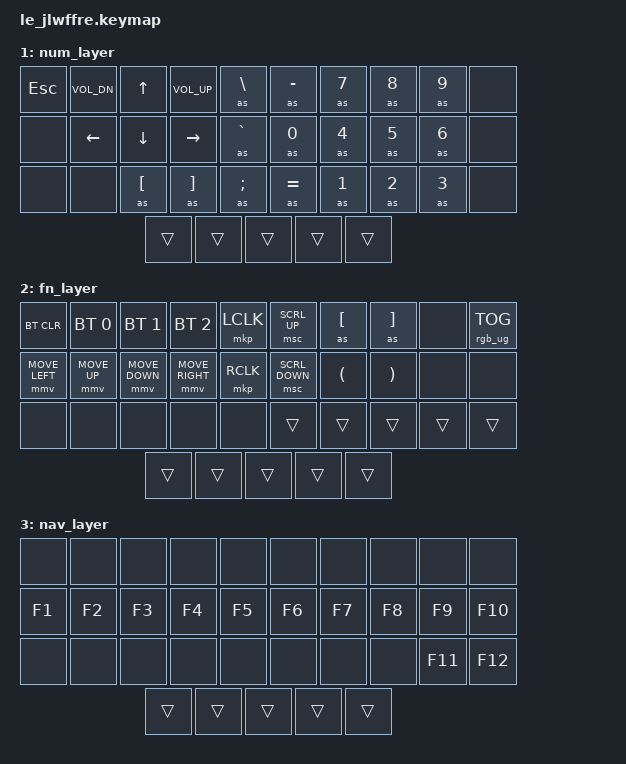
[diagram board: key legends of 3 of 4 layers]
/*
 * Copyright (c) 2022 The ZMK Contributors
 *
 * SPDX-License-Identifier: MIT
 */

#include <behaviors.dtsi>
#include <dt-bindings/zmk/keys.h>
#include <dt-bindings/zmk/bt.h>
#include <dt-bindings/zmk/pointing.h>
#include <dt-bindings/zmk/rgb.h>

// Home row mods macro - updated order: LSHIFT, LCTRL, lt 2, LALT (from center out)
#define HRML(k1,k2,k3,k4) &ht LALT k1 &lt 2 k2 &ht LCTRL k3 &ht LSHIFT k4
#define HRMR(k1,k2,k3,k4) &ht RSHIFT k1 &ht RCTRL k2 &lt 2 k3 &ht RALT k4

/ {

    behaviors {
        ht: hold_tap {
            compatible = "zmk,behavior-hold-tap";
            #binding-cells = <2>;   
            flavor = "balanced";
            tapping-term-ms = <200>;
            quick-tap-ms = <220>;
            require-prior-idle-ms = <125>;
            bindings = <&kp>, <&kp>;
        };
        mt: mod_tap {
            #binding-cells = <2>;
            tapping-term-ms = <200>;
            quick-tap-ms = <220>;
            require-prior-idle-ms = <125>;
            bindings = <&kp>, <&kp>;
        };
        as_ht: autoshift_hold_tap {
            compatible = "zmk,behavior-hold-tap";
            #binding-cells = <2>;
            tapping-term-ms = <200>;
            bindings = <&shifted>, <&kp>;
            flavor = "tap-preferred";
        };

        combos {
            compatible = "zmk,combos";
            combo_esc {     
                timeout-ms = <40>;
                key-positions = <0 1>;
                bindings = <&kp ESC>;
            };
            combo_del {
                timeout-ms = <40>;
                key-positions = <7 8>;
                bindings = <&kp DEL>;
            };
	    combo_F3 {
		timeout-ms = <40>;
		key-positions = <2 3>;
		bindings = <&kp F3>;
	    };
	    combo_enter {
		timeout-ms = <40>;
		key-positions = <6 7>; 	
		bindings = <&kp ENTER>;
	    };
	    combo_l3 {
		timeout-ms = <50>;
		key-positions = <20 21>;
		bindings = <&mo 3>;
	    };
            combo_reset {
                timeout-ms = <50>;
                key-positions = <0 9>;
                layers = <2>;
                bindings = <&sys_reset>;
            };
            combo_boot {
                timeout-ms = <50>;
                key-positions = <5 20>;
                layers = <2>;
                bindings = <&bootloader>;
            };
        };
    };

    macros {
        shifted: macro_shifted_kp {
            #binding-cells = <1>;
            compatible = "zmk,behavior-macro-one-param";
            bindings =
              <&macro_press &kp LSHFT>,
              <&macro_param_1to1 &macro_tap &kp MACRO_PLACEHOLDER>,
              <&macro_release &kp LSHFT>;
        };
        as: autoshift {
            compatible = "zmk,behavior-macro-one-param";
            #binding-cells = <1>;
            bindings =
              <&macro_press>,
              <&macro_param_1to1>,
              <&macro_param_1to2>,
              <&as_ht MACRO_PLACEHOLDER MACRO_PLACEHOLDER>,
              <&macro_pause_for_release>,
              <&macro_release>,
              <&macro_param_1to1>,
              <&macro_param_1to2>,
              <&as_ht MACRO_PLACEHOLDER MACRO_PLACEHOLDER>;
        };
    };

    keymap {
        compatible = "zmk,keymap";
        default_layer {
            bindings = <
        //╭──────────┬──────────┬──────────┬──────────┬──────────╮                      ╭──────────┬──────────┬──────────┬──────────┬──────────╮
        //│  Q       │  D       │  R       │  W       │  B       │                      │  J       │  F       │  U       │  P       │ ' "      │
            &kp Q      &kp D      &kp R      &kp W      &kp B                             &kp J      &kp F      &kp U      &kp P      &as SQT
        //├──────────┼──────────┼──────────┼──────────┼──────────┤                      ├──────────┼──────────┼──────────┼──────────┼──────────┤
        //│  A       │  S       │  H       │  T       │  G       │                      │  Y       │  N       │  E       │  I       │ O        │
            HRML(A,     S,         H,         T)         &kp G                             &kp Y     HRMR(N,     E,         O,         I)
        //├──────────┼──────────┼──────────┼──────────┼──────────┤                      ├──────────┼──────────┼──────────┼──────────┼──────────┤
        //│  Z       │  X       │  M       │  C       │  V       │                      │  K       │  H       │ , <      │ . >      │ / ?      │
            &kp Z      &kp X      &kp M      &kp C      &kp V                             &kp K      &kp L      &as COMMA  &as DOT    &as FSLH
        //╰──────────┴──────────┴──────────┼──────────┼──────────┤                      ├──────────┼──────────┼──────────┴──────────┴──────────╯
                                            &mt LGUI TAB  &lt 1 BSPC    &none           &lt 1 SPACE &mt RGUI RET
        //                                 ╰──────────┴──────────╯                      ╰──────────┴──────────╯
            >;
            sensor-bindings = <&inc_dec_kp C_VOL_UP C_VOL_DN>;
        };

        num_layer {
            bindings = <
        //╭──────────┬──────────┬──────────┬──────────┬──────────╮      ╭──────────┬──────────┬──────────┬──────────┬──────────╮
        //│          │  VOLUP   │   UP     │  VOLDN   │   \ _    │      │  - _     │    7 &   │    8 *   │    9     │          │
            &kp ESC  &kp C_VOL_DN  &kp UP   &kp C_VOL_UP &as BSLH        &as MINUS    &as N7    &as N8     &as N9      &none
        //├──────────┼──────────┼──────────┼──────────┼──────────┤      ├──────────+──────────┼──────────┼──────────┼──────────┤
        //│          │   LEFT   │   DOWN   │  RIGHT   │     ` ~  │      │   0 )    │  4 $     │  5 %     │  6 ^     │          │
            &none      &kp LEFT   &kp DOWN   &kp RIGHT   &as GRAVE        &as N0       &as N4     &as N5     &as N6    &none
        //├──────────┼──────────┼──────────┼──────────┼──────────┤      ├──────────┼──────────┼──────────┼──────────┼──────────┤
        //│          │          │    [ {   │    ] }   │          │      │          │  1!      │   2@     │    3#    │          │
            &none      &none       &as LBKT   &as RBKT   &as SEMI         &as EQUAL   &as N1     &as N2     &as N3     &none
        //╰──────────┴──────────┴──────────┼──────────┼──────────┤      ├──────────┼──────────┼──────────┴──────────┴──────────╯
                                             &trans     &trans    &trans  &trans     &trans
        //                                 ╰──────────┴──────────╯      ╰──────────┴──────────╯
            >;
            sensor-bindings = <&inc_dec_kp C_VOL_UP C_VOL_DN>;
        };

        fn_layer {
            bindings = <
        //╭──────────┬──────────┬──────────┬──────────┬──────────╮      ╭──────────┬──────────┬──────────┬──────────┬──────────╮
        //│          │          │          │          │          │      │          │     [ {  │    ]}    │          │          │
	&bt BT_CLR  &bt BT_SEL 0 &bt BT_SEL 1 &bt BT_SEL 2 &mkp LCLK     &msc SCRL_UP &as LBKT   &as RBKT    &none     &rgb_ug RGB_TOG  
        //├──────────┼──────────┼──────────┼──────────┼──────────┤      ├──────────┼──────────┼──────────┼──────────┼──────────┤
        //│          │          │          │          │          │      │          │     (    │    )     │          │          │
   &mmv MOVE_LEFT &mmv MOVE_UP &mmv MOVE_DOWN &mmv MOVE_RIGHT	&mkp RCLK  &msc SCRL_DOWN &kp LPAR &kp RPAR   &none    &none
        //├──────────┼──────────┼──────────┼──────────┼──────────┤      ├──────────┼──────────┼────;──────┼──────────┼──────────┤
        //│          │          │          │          │          │      │          │          │          │          │          │
            &none      &none      &none      &none      &none             &trans     &trans      &trans     &trans      &trans
        //╰──────────┴──────────┴──────────┼──────────┼──────────┤      ├──────────┼──────────┼──────────┴──────────┴──────────╯
                                             &trans     &trans    &trans  &trans     &trans
        //                                 ╰──────────┴──────────╯      ╰──────────┴──────────╯
            >;
            sensor-bindings = <&inc_dec_kp C_VOL_UP C_VOL_DN>;
        };

        nav_layer {
            bindings = <
        //╭──────────┬──────────┬──────────┬──────────┬──────────╮      ╭──────────┬──────────┬──────────┬──────────┬──────────╮
        //│          │          │          │          │          │      │          │          │          │          │          │
            &none      &none      &none       &none       &none          &none     &none      &none       &none      &none
        //├──────────┼──────────┼──────────┼──────────┼──────────┤      ├──────────┼──────────┼──────────┼──────────┼──────────┤
        //│          │          │          │          │          │      │          │          │          │          │          │
            &kp F1      &kp F2      &kp F3     &kp F4    &kp F5           &kp F6     &kp F7	 &kp F8     &kp F9     &kp F10
        //├──────────┼──────────┼──────────┼──────────┼──────────┤      ├──────────┼──────────┼──────────┼──────────┼──────────┤
        //│          │          │          │          │          │      │          │          │          │          │          │
            &none      &none      &none        &none      &none            &none      &none      &none      &kp F11     &kp F12
        //╰──────────┴──────────┴──────────┼──────────┼──────────┤      ├──────────┼──────────┼──────────┴──────────┴──────────╯
                                             &trans     &trans    &trans  &trans     &trans
        //                                 ╰──────────┴──────────╯      ╰──────────┴──────────╯
            >;
            sensor-bindings = <&inc_dec_kp C_VOL_UP C_VOL_DN>;
        };

    };

};
